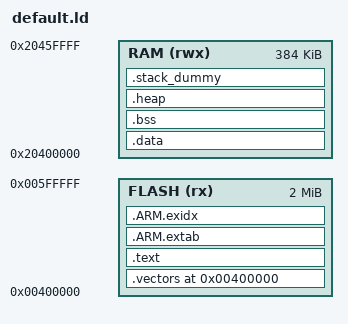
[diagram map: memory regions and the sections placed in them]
/**
 * Copyright (c) 2016-2017 Microchip Technology Inc. All rights reserved.
 *
 * Licensed under the Apache License, Version 2.0 (the "License");
 * you may not use this file except in compliance with the License.
 * You may obtain a copy of the License at
 *
 *   http://www.apache.org/licenses/LICENSE-2.0
 *
 * Unless required by applicable law or agreed to in writing, software
 * distributed under the License is distributed on an "AS IS" BASIS,
 * WITHOUT WARRANTIES OR CONDITIONS OF ANY KIND, either express or implied.
 * See the License for the specific language governing permissions and
 * limitations under the License.
 */

/* Source file is GNU Tools ARM Embedded 5.4 2016q3 \share\gcc-arm-none-eabi\samples\ldscripts\gcc.ld */

/* Linker script to configure memory regions.
 * Need modifying for a specific board.
 *   FLASH.ORIGIN: starting address of flash
 *   FLASH.LENGTH: length of flash
 *   RAM.ORIGIN: starting address of RAM bank 0
 *   RAM.LENGTH: length of RAM bank 0
 */
MEMORY
{
  FLASH (rx) : ORIGIN = 0x00400000, LENGTH = 0x00200000
  RAM (rwx) : ORIGIN = 0x20400000, LENGTH = 0x00060000
}

/* The stack size used by the application. NOTE: you need to adjust according to your application. */
/*STACK_SIZE = DEFINED(STACK_SIZE) ? STACK_SIZE : 0x0400;*/
STACK_SIZE = 1024;

/* The heapsize used by the application. NOTE: you need to adjust according to your application. */
/* HEAP_SIZE = DEFINED(HEAP_SIZE) ? HEAP_SIZE : 0x0200; */
HEAP_SIZE = 0;

/* Linker script to place sections and symbol values. Should be used together
 * with other linker script that defines memory regions FLASH and RAM.
 * It references following symbols, which must be defined in code:
 *   Reset_Handler : Entry of reset handler
 *
 * It defines following symbols, which code can use without definition:
 *   __exidx_start
 *   __exidx_end
 *   __copy_table_start__
 *   __copy_table_end__
 *   __zero_table_start__
 *   __zero_table_end__
 *   __etext
 *   __data_start__
 *   __preinit_array_start
 *   __preinit_array_end
 *   __init_array_start
 *   __init_array_end
 *   __fini_array_start
 *   __fini_array_end
 *   __data_end__
 *   __bss_start__
 *   __bss_end__
 *   __end__ = _end = __HeapStart
 *   __HeapLimit
 *   __StackLimit
 *   __StackTop
 *   __stack
 *   __ram_end__
 */
ENTRY(Reset_Handler)

GROUP(
  libm.a
  libgcc.a
  libc_nano.a
  libg_nano.a
  libstdc++_nano.a
  libsupc++_nano.a
)

SECTIONS
{
  . = ORIGIN(FLASH);

  .vectors :
  {
    KEEP(*(.flash_vectors))
  } > FLASH

  .text :
  {
    *(.text*)

    KEEP(*(.init))
    KEEP(*(.fini))

    /* .ctors */
    *crtbegin.o(.ctors)
    *crtbegin?.o(.ctors)
    *(EXCLUDE_FILE(*crtend?.o *crtend.o) .ctors)
    *(SORT(.ctors.*))
    *(.ctors)

    /* .dtors */
    *crtbegin.o(.dtors)
    *crtbegin?.o(.dtors)
    *(EXCLUDE_FILE(*crtend?.o *crtend.o) .dtors)
    *(SORT(.dtors.*))
    *(.dtors)

    *(.rodata*)

    KEEP(*(.eh_frame*))
  } > FLASH

  .ARM.extab :
  {
    *(.ARM.extab* .gnu.linkonce.armextab.*)
  } > FLASH

  __exidx_start = .;
  .ARM.exidx :
  {
    *(.ARM.exidx* .gnu.linkonce.armexidx.*)
  } > FLASH
  __exidx_end = .;

  /* To copy multiple ROM to RAM sections,
   * uncomment .copy.table section and,
   * define __STARTUP_COPY_MULTIPLE in startup_ARMCMx.S */
  /*
  .copy.table :
  {
    . = ALIGN(4);
    __copy_table_start__ = .;
    LONG (__etext)
    LONG (__data_start__)
    LONG (__data_end__ - __data_start__)
    LONG (__etext2)
    LONG (__data2_start__)
    LONG (__data2_end__ - __data2_start__)
    __copy_table_end__ = .;
  } > FLASH
  */

  /* To clear multiple BSS sections,
   * uncomment .zero.table section and,
   * define __STARTUP_CLEAR_BSS_MULTIPLE in startup_ARMCMx.S */
  /*
  .zero.table :
  {
    . = ALIGN(4);
    __zero_table_start__ = .;
    LONG (__bss_start__)
    LONG (__bss_end__ - __bss_start__)
    LONG (__bss2_start__)
    LONG (__bss2_end__ - __bss2_start__)
    __zero_table_end__ = .;
  } > FLASH
  */

  __etext = .;

  .data : AT (__etext)
  {
    __data_start__ = .;
    *(vtable)
    *(.data*)
    *(.ramfunc*)

    . = ALIGN(4);
    /* preinit data */
    PROVIDE_HIDDEN (__preinit_array_start = .);
    KEEP(*(.preinit_array))
    PROVIDE_HIDDEN (__preinit_array_end = .);

    . = ALIGN(4);
    /* init data */
    PROVIDE_HIDDEN (__init_array_start = .);
    KEEP(*(SORT(.init_array.*)))
    KEEP(*(.init_array))
    PROVIDE_HIDDEN (__init_array_end = .);

    . = ALIGN(4);
    /* finit data */
    PROVIDE_HIDDEN (__fini_array_start = .);
    KEEP(*(SORT(.fini_array.*)))
    KEEP(*(.fini_array))
    PROVIDE_HIDDEN (__fini_array_end = .);

    KEEP(*(.jcr*))
    . = ALIGN(4);
    /* All data end */
    __data_end__ = .;

  } > RAM
/* todo
  } > RAM AT > FLASH
*/

  .bss :
  {
    . = ALIGN(4);
    __bss_start__ = .;
    *(.bss*)
    *(COMMON)
    . = ALIGN(4);
    __bss_end__ = .;
  } > RAM

  .heap (NOLOAD):
  {
    __end__ = .;
    PROVIDE(__HeapStart = .);
    PROVIDE(_end = .);
    *(.heap*)
    . = . + HEAP_SIZE;
    . = ALIGN(4);
    __HeapLimit = .;
  } > RAM

  /* .stack_dummy section doesn't contains any symbols. It is only
   * used for linker to calculate size of stack sections, and assign
   * values to stack symbols later */
  .stack_dummy (NOLOAD):
  {
    *(.stack*)
  } > RAM

  /* Set stack top to end of RAM, and stack limit move down by
   * size of stack_dummy section */
  __StackTop = ORIGIN(RAM) + LENGTH(RAM);
  __StackBottom = ORIGIN(RAM) + LENGTH(RAM) - STACK_SIZE;
  __StackLimit = __StackTop - SIZEOF(.stack_dummy);
  PROVIDE(__stack = __StackTop);

  __ram_end__ = ORIGIN(RAM) + LENGTH(RAM) -1 ;

  /* Check if data + heap + stack exceeds RAM limit */
  ASSERT(__StackLimit >= __HeapLimit, "region RAM overflowed with stack")
}
